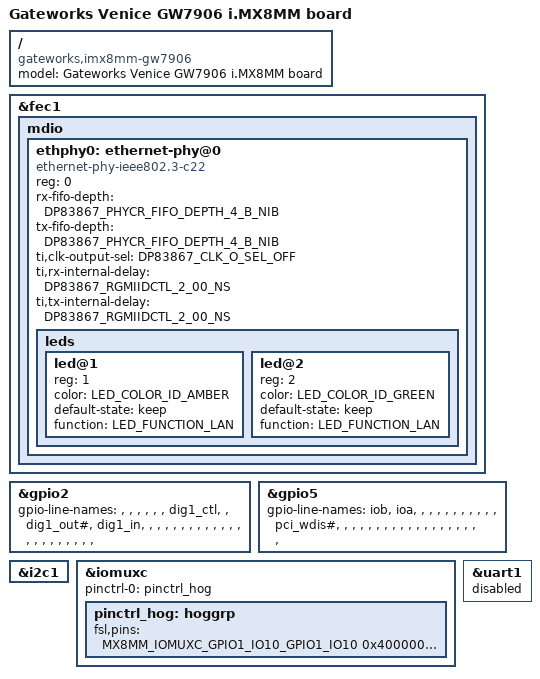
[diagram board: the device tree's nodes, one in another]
// SPDX-License-Identifier: (GPL-2.0+ OR MIT)
/*
 * Copyright 2026 Gateworks Corporation
 */

/dts-v1/;

#include <dt-bindings/net/ti-dp83867.h>

#include "imx8mm-venice-gw7903.dts"

/ {
	compatible = "gateworks,imx8mm-gw7906", "fsl,imx8mm";
	model = "Gateworks Venice GW7906 i.MX8MM board";
};

&fec1 {
	mdio {
		#address-cells = <1>;
		#size-cells = <0>;

		ethphy0: ethernet-phy@0 {
			compatible = "ethernet-phy-ieee802.3-c22";
			reg = <0>;
			rx-fifo-depth = <DP83867_PHYCR_FIFO_DEPTH_4_B_NIB>;
			tx-fifo-depth = <DP83867_PHYCR_FIFO_DEPTH_4_B_NIB>;
			ti,clk-output-sel = <DP83867_CLK_O_SEL_OFF>;
			ti,rx-internal-delay = <DP83867_RGMIIDCTL_2_00_NS>;
			ti,tx-internal-delay = <DP83867_RGMIIDCTL_2_00_NS>;

			leds {
				#address-cells = <1>;
				#size-cells = <0>;

				led@1 {
					reg = <1>;
					color = <LED_COLOR_ID_AMBER>;
					default-state = "keep";
					function = LED_FUNCTION_LAN;
				};

				led@2 {
					reg = <2>;
					color = <LED_COLOR_ID_GREEN>;
					default-state = "keep";
					function = LED_FUNCTION_LAN;
				};
			};
		};
	};
};

&gpio2 {
	gpio-line-names = "", "", "", "", "", "", "dig1_ctl", "",
		"dig1_out#", "dig1_in", "", "", "", "", "", "",
		"", "", "", "", "", "", "", "",
		"", "", "", "", "", "", "", "";
};

&gpio5 {
	gpio-line-names = "iob", "ioa", "", "", "", "", "", "",
		"", "", "", "", "pci_wdis#", "", "", "",
		"", "", "", "", "", "", "", "",
		"", "", "", "", "", "", "", "";
};

&i2c1 {
	/delete-node/ gpio@27;
};

&iomuxc {
	pinctrl-0 = <&pinctrl_hog>;
	pinctrl-names = "default";

	pinctrl_hog: hoggrp {
		fsl,pins = <
			MX8MM_IOMUXC_GPIO1_IO10_GPIO1_IO10	0x40000041 /* RS422# */
			MX8MM_IOMUXC_GPIO1_IO11_GPIO1_IO11	0x40000041 /* RS485# */
			MX8MM_IOMUXC_GPIO1_IO12_GPIO1_IO12	0x40000041 /* RS232# */
			MX8MM_IOMUXC_SD1_DATA7_GPIO2_IO9	0x40000041 /* DIG1_IN */
			MX8MM_IOMUXC_SD1_DATA6_GPIO2_IO8	0x40000041 /* DIG1_OUT */
			MX8MM_IOMUXC_SD1_DATA4_GPIO2_IO6	0x40000041 /* DIG1_CTL */
			MX8MM_IOMUXC_ECSPI2_MISO_GPIO5_IO12	0x40000041 /* PCI_WDIS# */
			MX8MM_IOMUXC_SAI3_TXD_GPIO5_IO1		0x40000041 /* IOA */
			MX8MM_IOMUXC_SAI3_TXC_GPIO5_IO0		0x40000041 /* IOB */
		>;
	};
};

&uart1 {
	status = "disabled";
};
